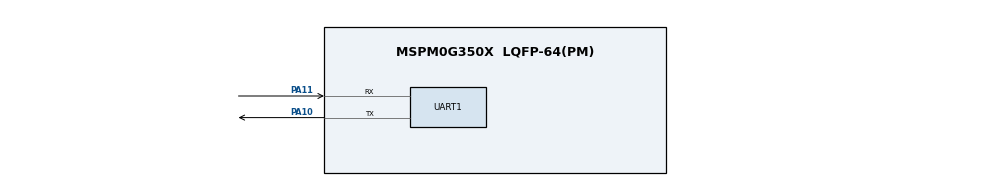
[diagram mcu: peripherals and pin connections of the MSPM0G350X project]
/**
 * @cliArgs --device "MSPM0G350X" --part "Default" --package "LQFP-64(PM)" --product "mspm0_sdk@2.05.00.05"
 * @versions {"tool":"1.24.0+4150"}
 */

/**
 * Import the modules used in this configuration.
 */
const SYSCTL = scripting.addModule("/ti/driverlib/SYSCTL");
const UART   = scripting.addModule("/ti/driverlib/UART", {}, false);
const UART1  = UART.addInstance();
const UART2  = UART.addInstance();

/**
 * Write custom configuration values to the imported modules.
 */
SYSCTL.forceDefaultClkConfig = true;

const Board = scripting.addModule("/ti/driverlib/Board", {}, false);

UART1.$name                            = "UART_BT";
UART1.peripheral.rxPin.$assign         = "PA11";
UART1.peripheral.txPin.$assign         = "PA10";
UART1.txPinConfig.$name                = "ti_driverlib_gpio_GPIOPinGeneric0";
UART1.txPinConfig.direction            = scripting.forceWrite("OUTPUT");
UART1.txPinConfig.hideOutputInversion  = scripting.forceWrite(false);
UART1.txPinConfig.onlyInternalResistor = scripting.forceWrite(false);
UART1.txPinConfig.passedPeripheralType = scripting.forceWrite("Digital");
UART1.rxPinConfig.$name                = "ti_driverlib_gpio_GPIOPinGeneric1";
UART1.rxPinConfig.hideOutputInversion  = scripting.forceWrite(false);
UART1.rxPinConfig.onlyInternalResistor = scripting.forceWrite(false);
UART1.rxPinConfig.passedPeripheralType = scripting.forceWrite("Digital");

UART2.$name                            = "UART_openMV";
UART2.txPinConfig.$name                = "ti_driverlib_gpio_GPIOPinGeneric2";
UART2.txPinConfig.direction            = scripting.forceWrite("OUTPUT");
UART2.txPinConfig.hideOutputInversion  = scripting.forceWrite(false);
UART2.txPinConfig.onlyInternalResistor = scripting.forceWrite(false);
UART2.txPinConfig.passedPeripheralType = scripting.forceWrite("Digital");
UART2.rxPinConfig.$name                = "ti_driverlib_gpio_GPIOPinGeneric3";
UART2.rxPinConfig.hideOutputInversion  = scripting.forceWrite(false);
UART2.rxPinConfig.onlyInternalResistor = scripting.forceWrite(false);
UART2.rxPinConfig.passedPeripheralType = scripting.forceWrite("Digital");

/**
 * Pinmux solution for unlocked pins/peripherals. This ensures that minor changes to the automatic solver in a future
 * version of the tool will not impact the pinmux you originally saw.  These lines can be completely deleted in order to
 * re-solve from scratch.
 */
SYSCTL.peripheral.$suggestSolution         = "SYSCTL";
Board.peripheral.$suggestSolution          = "DEBUGSS";
Board.peripheral.swclkPin.$suggestSolution = "PA20";
Board.peripheral.swdioPin.$suggestSolution = "PA19";
UART1.peripheral.$suggestSolution          = "UART0";
UART2.peripheral.$suggestSolution          = "UART1";
UART2.peripheral.rxPin.$suggestSolution    = "PA18";
UART2.peripheral.txPin.$suggestSolution    = "PA17";
